# CBASS_CBASS_FW_45000000h register map
Vendor: Texas Instruments
Peripheral module from a debugger description file (folder AM275x).
Registers are 32-bit, read-write, reset 0x0 unless marked. A register's access mark holds for its fields unless they carry their own. Offsets are as the file gives them; lines under a group give offsets from that group; [hi:lo] are bit positions; {n}, {i} and the like mark numbered series; 'fields as' and 'values as' point back to an identical list; <NAME> marks a mode.

## cbass_fw
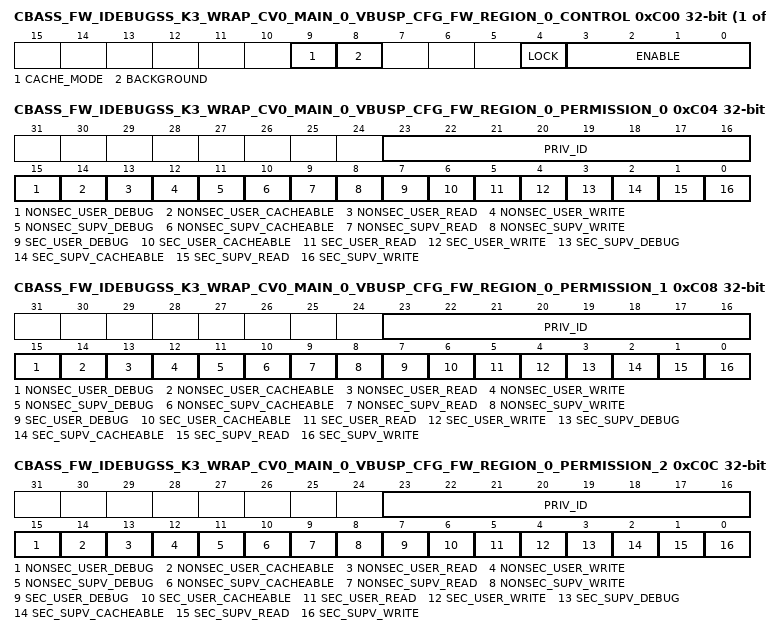
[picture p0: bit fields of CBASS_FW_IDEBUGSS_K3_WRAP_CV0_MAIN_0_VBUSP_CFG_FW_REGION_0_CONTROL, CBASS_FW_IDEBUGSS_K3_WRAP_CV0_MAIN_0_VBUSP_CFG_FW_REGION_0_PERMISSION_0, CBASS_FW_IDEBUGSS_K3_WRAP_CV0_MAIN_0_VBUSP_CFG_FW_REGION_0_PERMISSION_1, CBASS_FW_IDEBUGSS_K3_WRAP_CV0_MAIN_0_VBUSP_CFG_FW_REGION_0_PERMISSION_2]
{0xC00+0x20*i} CBASS_FW_IDEBUGSS_K3_WRAP_CV0_MAIN_0_VBUSP_CFG_FW_REGION_{i}_CONTROL access not given (i=0..3) — The FW Region {i} Control Register defines the control fields for the target Idebugss_k3_wrap_cv0_main_0.vbusp_cfg region {i} firewall.
  [9] CACHE_MODE rw — Cache mode for region. Set to 1 to check cache permissions. Set to 0 to ignore cache permissions. Reset Source: domain_default_rst_mod_g_rst_n
  [8] BACKGROUND rw — Background enable for region. There can be 1 backgroun region per FW and foreground regions can have overlapping addresses only with the background region. Reset Source: domain_default_rst_mod_g_rst_n
  [4] LOCK — Lock region. Once set region values cannot be modified. Reset Source: domain_default_rst_mod_g_rst_n (access R/W1TS)
  [3:0] ENABLE rw — Enable region. A value of 0xA enables, others disable. Reset Source: domain_default_rst_mod_g_rst_n
{0xC04+0x20*i} CBASS_FW_IDEBUGSS_K3_WRAP_CV0_MAIN_0_VBUSP_CFG_FW_REGION_{i}_PERMISSION_0 (i=0..3) — The FW Region {i} Permission 0 Register defines the permissions for the target Idebugss_k3_wrap_cv0_main_0.vbusp_cfg region {i} firewall.
  [23:16] PRIV_ID — Allowed privid. Reset Source: domain_default_rst_mod_g_rst_n
  [15] NONSEC_USER_DEBUG — Non-secure user debug allowed. Reset Source: domain_default_rst_mod_g_rst_n
  [14] NONSEC_USER_CACHEABLE — Non-secure user cacheable allowed. Reset Source: domain_default_rst_mod_g_rst_n
  [13] NONSEC_USER_READ — Non-secure user read allowed. Reset Source: domain_default_rst_mod_g_rst_n
  [12] NONSEC_USER_WRITE — Non-secure user write allowed. Reset Source: domain_default_rst_mod_g_rst_n
  [11] NONSEC_SUPV_DEBUG — Non-secure supervisor debug allowed. Reset Source: domain_default_rst_mod_g_rst_n
  [10] NONSEC_SUPV_CACHEABLE — Non-secure supervisor cacheable allowed. Reset Source: domain_default_rst_mod_g_rst_n
  [9] NONSEC_SUPV_READ — Non-secure supervisor read allowed. Reset Source: domain_default_rst_mod_g_rst_n
  [8] NONSEC_SUPV_WRITE — Non-secure supervisor write allowed. Reset Source: domain_default_rst_mod_g_rst_n
  [7] SEC_USER_DEBUG — Secure user debug allowed. Reset Source: domain_default_rst_mod_g_rst_n
  [6] SEC_USER_CACHEABLE — Secure user cacheable allowed. Reset Source: domain_default_rst_mod_g_rst_n
  [5] SEC_USER_READ — Secure user read allowed. Reset Source: domain_default_rst_mod_g_rst_n
  [4] SEC_USER_WRITE — Secure user write allowed. Reset Source: domain_default_rst_mod_g_rst_n
  [3] SEC_SUPV_DEBUG — Secure supervisor debug allowed. Reset Source: domain_default_rst_mod_g_rst_n
  [2] SEC_SUPV_CACHEABLE — Secure supervisor cacheable allowed. Reset Source: domain_default_rst_mod_g_rst_n
  [1] SEC_SUPV_READ — Secure supervisor read allowed. Reset Source: domain_default_rst_mod_g_rst_n
  [0] SEC_SUPV_WRITE — Secure supervisor write allowed. Reset Source: domain_default_rst_mod_g_rst_n
{0xC08+0x20*i} CBASS_FW_IDEBUGSS_K3_WRAP_CV0_MAIN_0_VBUSP_CFG_FW_REGION_{i}_PERMISSION_1 (i=0..3) — The FW Region {i} Permission 1 Register defines the permissions for the target Idebugss_k3_wrap_cv0_main_0.vbusp_cfg region {i} firewall.
  fields as CBASS_FW_IDEBUGSS_K3_WRAP_CV0_MAIN_0_VBUSP_CFG_FW_REGION_0_PERMISSION_0
{0xC0C+0x20*i} CBASS_FW_IDEBUGSS_K3_WRAP_CV0_MAIN_0_VBUSP_CFG_FW_REGION_{i}_PERMISSION_2 (i=0..3) — The FW Region {i} Permission 2 Register defines the permissions for the target Idebugss_k3_wrap_cv0_main_0.vbusp_cfg region {i} firewall.
  fields as CBASS_FW_IDEBUGSS_K3_WRAP_CV0_MAIN_0_VBUSP_CFG_FW_REGION_0_PERMISSION_0
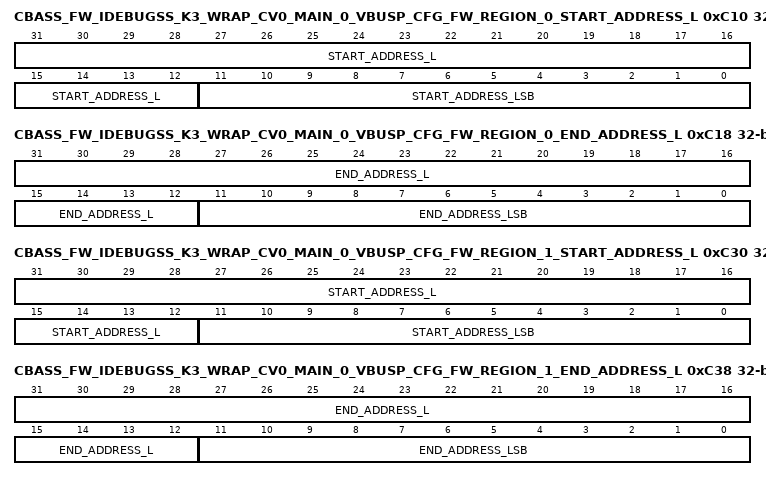
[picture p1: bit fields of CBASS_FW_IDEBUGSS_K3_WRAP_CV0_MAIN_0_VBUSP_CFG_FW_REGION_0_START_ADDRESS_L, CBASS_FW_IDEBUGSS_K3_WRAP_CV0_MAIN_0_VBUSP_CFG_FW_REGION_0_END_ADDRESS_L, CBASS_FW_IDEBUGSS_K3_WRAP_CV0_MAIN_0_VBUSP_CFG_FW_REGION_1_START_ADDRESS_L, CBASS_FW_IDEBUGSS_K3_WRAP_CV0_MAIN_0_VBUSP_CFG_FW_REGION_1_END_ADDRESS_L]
0xC10 CBASS_FW_IDEBUGSS_K3_WRAP_CV0_MAIN_0_VBUSP_CFG_FW_REGION_0_START_ADDRESS_L access per field — The FW Region 0 Start Address Low Register defines the start address bits 31 to 0 for the target Idebugss_k3_wrap_cv0_main_0.vbusp_cfg region 0 firewall.
  [31:12] START_ADDRESS_L rw — Start address bits 31 to 12. Lowest 12 bits are forced to 0 as address must be 4KB aligned. Reset Source: domain_default_rst_mod_g_rst_n
  [11:0] START_ADDRESS_LSB ro — Start address bits 11 to 0 are forced to 0 as address must be 4KB aligned. Reset Source: domain_default_rst_mod_g_rst_n
{0xC14+0x20*i} CBASS_FW_IDEBUGSS_K3_WRAP_CV0_MAIN_0_VBUSP_CFG_FW_REGION_{i}_START_ADDRESS_H reset 0x7 (i=0..3) — The FW Region {i} Start Address High Register defines the start address bits 47 to 32 for the target Idebugss_k3_wrap_cv0_main_0.vbusp_cfg region {i} firewall.
  [15:0] START_ADDRESS_H — Start address bits 47 to 32. Reset Source: domain_default_rst_mod_g_rst_n
0xC18 CBASS_FW_IDEBUGSS_K3_WRAP_CV0_MAIN_0_VBUSP_CFG_FW_REGION_0_END_ADDRESS_L access per field reset 0xFFF — The FW Region 0 End Address Low Register defines the end address bits 31 to 0 to include for the target Idebugss_k3_wrap_cv0_main_0.vbusp_cfg region 0 firewall.
  [31:12] END_ADDRESS_L rw — End address bits 31 to 12 to include in the match. Lowest 12 bits are forced to 1s as address must be 4KB aligned. Reset Source: domain_default_rst_mod_g_rst_n
  [11:0] END_ADDRESS_LSB ro — End address bits 11 to 0 are forced to 1s as address must be 4KB aligned minus 1. Reset Source: domain_default_rst_mod_g_rst_n
{0xC1C+0x20*i} CBASS_FW_IDEBUGSS_K3_WRAP_CV0_MAIN_0_VBUSP_CFG_FW_REGION_{i}_END_ADDRESS_H reset 0x7 (i=0..3) — The FW Region {i} End Address High Register defines the end address bits 47 to 32 to include for the target Idebugss_k3_wrap_cv0_main_0.vbusp_cfg region {i} firewall.
  [15:0] END_ADDRESS_H — End address bits 47 to 32 to include in the match. Reset Source: domain_default_rst_mod_g_rst_n
0xC30 CBASS_FW_IDEBUGSS_K3_WRAP_CV0_MAIN_0_VBUSP_CFG_FW_REGION_1_START_ADDRESS_L access per field reset 0x1000 — The FW Region 1 Start Address Low Register defines the start address bits 31 to 0 for the target Idebugss_k3_wrap_cv0_main_0.vbusp_cfg region 1 firewall.
  fields as CBASS_FW_IDEBUGSS_K3_WRAP_CV0_MAIN_0_VBUSP_CFG_FW_REGION_0_START_ADDRESS_L
0xC38 CBASS_FW_IDEBUGSS_K3_WRAP_CV0_MAIN_0_VBUSP_CFG_FW_REGION_1_END_ADDRESS_L access per field reset 0x1FFF — The FW Region 1 End Address Low Register defines the end address bits 31 to 0 to include for the target Idebugss_k3_wrap_cv0_main_0.vbusp_cfg region 1 firewall.
  fields as CBASS_FW_IDEBUGSS_K3_WRAP_CV0_MAIN_0_VBUSP_CFG_FW_REGION_0_END_ADDRESS_L
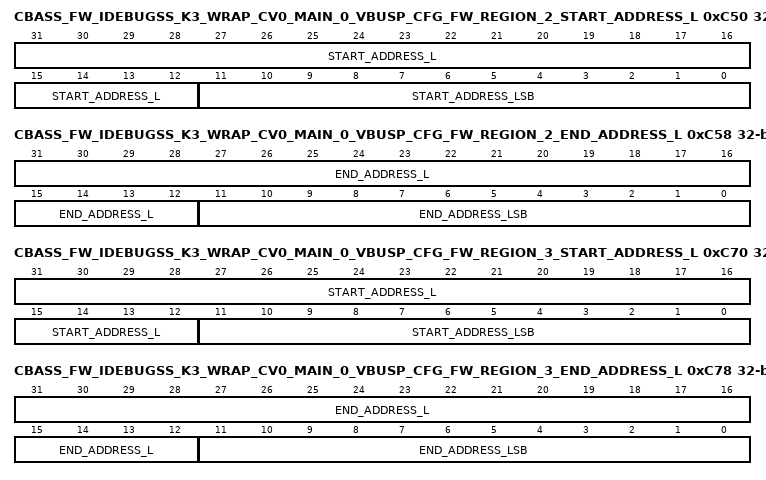
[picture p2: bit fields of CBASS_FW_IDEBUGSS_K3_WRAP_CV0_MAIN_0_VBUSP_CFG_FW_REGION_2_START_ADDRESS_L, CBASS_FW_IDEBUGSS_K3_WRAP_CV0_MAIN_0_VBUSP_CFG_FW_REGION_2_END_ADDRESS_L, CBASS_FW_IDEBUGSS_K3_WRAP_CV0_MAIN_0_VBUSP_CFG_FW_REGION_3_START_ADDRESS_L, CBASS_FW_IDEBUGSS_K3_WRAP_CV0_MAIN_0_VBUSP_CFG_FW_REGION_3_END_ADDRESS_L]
0xC50 CBASS_FW_IDEBUGSS_K3_WRAP_CV0_MAIN_0_VBUSP_CFG_FW_REGION_2_START_ADDRESS_L access per field reset 0x2000 — The FW Region 2 Start Address Low Register defines the start address bits 31 to 0 for the target Idebugss_k3_wrap_cv0_main_0.vbusp_cfg region 2 firewall.
  fields as CBASS_FW_IDEBUGSS_K3_WRAP_CV0_MAIN_0_VBUSP_CFG_FW_REGION_0_START_ADDRESS_L
0xC58 CBASS_FW_IDEBUGSS_K3_WRAP_CV0_MAIN_0_VBUSP_CFG_FW_REGION_2_END_ADDRESS_L access per field reset 0x2FFF — The FW Region 2 End Address Low Register defines the end address bits 31 to 0 to include for the target Idebugss_k3_wrap_cv0_main_0.vbusp_cfg region 2 firewall.
  fields as CBASS_FW_IDEBUGSS_K3_WRAP_CV0_MAIN_0_VBUSP_CFG_FW_REGION_0_END_ADDRESS_L
0xC70 CBASS_FW_IDEBUGSS_K3_WRAP_CV0_MAIN_0_VBUSP_CFG_FW_REGION_3_START_ADDRESS_L access per field reset 0x2000 — The FW Region 3 Start Address Low Register defines the start address bits 31 to 0 for the target Idebugss_k3_wrap_cv0_main_0.vbusp_cfg region 3 firewall.
  fields as CBASS_FW_IDEBUGSS_K3_WRAP_CV0_MAIN_0_VBUSP_CFG_FW_REGION_0_START_ADDRESS_L
0xC78 CBASS_FW_IDEBUGSS_K3_WRAP_CV0_MAIN_0_VBUSP_CFG_FW_REGION_3_END_ADDRESS_L access per field reset 0x2FFF — The FW Region 3 End Address Low Register defines the end address bits 31 to 0 to include for the target Idebugss_k3_wrap_cv0_main_0.vbusp_cfg region 3 firewall.
  fields as CBASS_FW_IDEBUGSS_K3_WRAP_CV0_MAIN_0_VBUSP_CFG_FW_REGION_0_END_ADDRESS_L
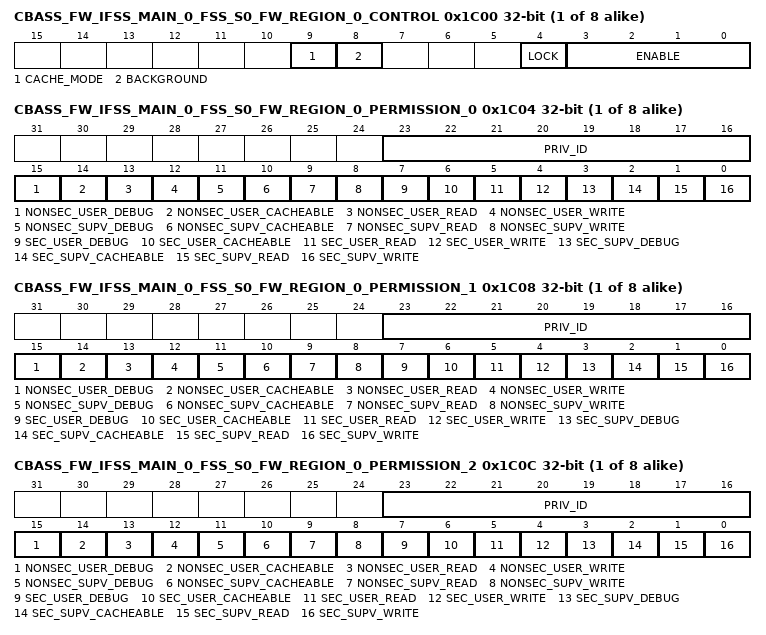
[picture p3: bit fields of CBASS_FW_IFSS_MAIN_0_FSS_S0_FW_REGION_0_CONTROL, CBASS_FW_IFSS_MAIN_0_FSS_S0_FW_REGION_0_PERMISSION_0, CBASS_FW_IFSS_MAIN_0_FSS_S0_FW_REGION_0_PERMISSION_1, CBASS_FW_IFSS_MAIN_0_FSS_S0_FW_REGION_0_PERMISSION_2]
{0x1C00+0x20*i} CBASS_FW_IFSS_MAIN_0_FSS_S0_FW_REGION_{i}_CONTROL access not given (i=0..7) — The FW Region {i} Control Register defines the control fields for the target Ifss_main_0.fss_s0 region {i} firewall.
  fields as CBASS_FW_IDEBUGSS_K3_WRAP_CV0_MAIN_0_VBUSP_CFG_FW_REGION_0_CONTROL
{0x1C04+0x20*i} CBASS_FW_IFSS_MAIN_0_FSS_S0_FW_REGION_{i}_PERMISSION_0 (i=0..7) — The FW Region {i} Permission 0 Register defines the permissions for the target Ifss_main_0.fss_s0 region {i} firewall.
  fields as CBASS_FW_IDEBUGSS_K3_WRAP_CV0_MAIN_0_VBUSP_CFG_FW_REGION_0_PERMISSION_0
{0x1C08+0x20*i} CBASS_FW_IFSS_MAIN_0_FSS_S0_FW_REGION_{i}_PERMISSION_1 (i=0..7) — The FW Region {i} Permission 1 Register defines the permissions for the target Ifss_main_0.fss_s0 region {i} firewall.
  fields as CBASS_FW_IDEBUGSS_K3_WRAP_CV0_MAIN_0_VBUSP_CFG_FW_REGION_0_PERMISSION_0
{0x1C0C+0x20*i} CBASS_FW_IFSS_MAIN_0_FSS_S0_FW_REGION_{i}_PERMISSION_2 (i=0..7) — The FW Region {i} Permission 2 Register defines the permissions for the target Ifss_main_0.fss_s0 region {i} firewall.
  fields as CBASS_FW_IDEBUGSS_K3_WRAP_CV0_MAIN_0_VBUSP_CFG_FW_REGION_0_PERMISSION_0
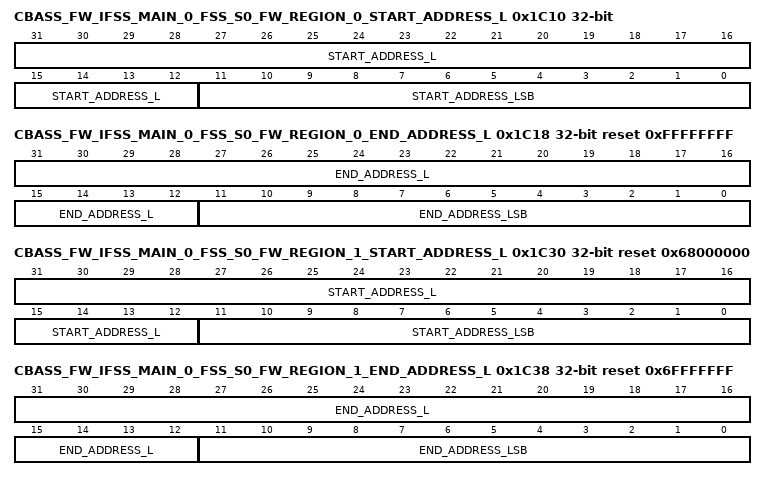
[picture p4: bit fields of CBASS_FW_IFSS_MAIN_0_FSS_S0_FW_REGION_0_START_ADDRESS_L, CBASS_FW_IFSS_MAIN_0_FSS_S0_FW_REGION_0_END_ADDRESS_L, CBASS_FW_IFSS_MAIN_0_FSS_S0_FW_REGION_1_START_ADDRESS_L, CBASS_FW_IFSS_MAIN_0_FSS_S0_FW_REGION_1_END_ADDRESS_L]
0x1C10 CBASS_FW_IFSS_MAIN_0_FSS_S0_FW_REGION_0_START_ADDRESS_L access per field — The FW Region 0 Start Address Low Register defines the start address bits 31 to 0 for the target Ifss_main_0.fss_s0 region 0 firewall.
  fields as CBASS_FW_IDEBUGSS_K3_WRAP_CV0_MAIN_0_VBUSP_CFG_FW_REGION_0_START_ADDRESS_L
0x1C14 CBASS_FW_IFSS_MAIN_0_FSS_S0_FW_REGION_0_START_ADDRESS_H reset 0x2 — The FW Region 0 Start Address High Register defines the start address bits 47 to 32 for the target Ifss_main_0.fss_s0 region 0 firewall.
  fields as CBASS_FW_IDEBUGSS_K3_WRAP_CV0_MAIN_0_VBUSP_CFG_FW_REGION_0_START_ADDRESS_H
0x1C18 CBASS_FW_IFSS_MAIN_0_FSS_S0_FW_REGION_0_END_ADDRESS_L access per field reset 0xFFFFFFFF — The FW Region 0 End Address Low Register defines the end address bits 31 to 0 to include for the target Ifss_main_0.fss_s0 region 0 firewall.
  fields as CBASS_FW_IDEBUGSS_K3_WRAP_CV0_MAIN_0_VBUSP_CFG_FW_REGION_0_END_ADDRESS_L
0x1C1C CBASS_FW_IFSS_MAIN_0_FSS_S0_FW_REGION_0_END_ADDRESS_H reset 0x2 — The FW Region 0 End Address High Register defines the end address bits 47 to 32 to include for the target Ifss_main_0.fss_s0 region 0 firewall.
  fields as CBASS_FW_IDEBUGSS_K3_WRAP_CV0_MAIN_0_VBUSP_CFG_FW_REGION_0_END_ADDRESS_H
0x1C30 CBASS_FW_IFSS_MAIN_0_FSS_S0_FW_REGION_1_START_ADDRESS_L access per field reset 0x68000000 — The FW Region 1 Start Address Low Register defines the start address bits 31 to 0 for the target Ifss_main_0.fss_s0 region 1 firewall.
  fields as CBASS_FW_IDEBUGSS_K3_WRAP_CV0_MAIN_0_VBUSP_CFG_FW_REGION_0_START_ADDRESS_L
0x1C34 CBASS_FW_IFSS_MAIN_0_FSS_S0_FW_REGION_1_START_ADDRESS_H — The FW Region 1 Start Address High Register defines the start address bits 47 to 32 for the target Ifss_main_0.fss_s0 region 1 firewall.
  fields as CBASS_FW_IDEBUGSS_K3_WRAP_CV0_MAIN_0_VBUSP_CFG_FW_REGION_0_START_ADDRESS_H
0x1C38 CBASS_FW_IFSS_MAIN_0_FSS_S0_FW_REGION_1_END_ADDRESS_L access per field reset 0x6FFFFFFF — The FW Region 1 End Address Low Register defines the end address bits 31 to 0 to include for the target Ifss_main_0.fss_s0 region 1 firewall.
  fields as CBASS_FW_IDEBUGSS_K3_WRAP_CV0_MAIN_0_VBUSP_CFG_FW_REGION_0_END_ADDRESS_L
0x1C3C CBASS_FW_IFSS_MAIN_0_FSS_S0_FW_REGION_1_END_ADDRESS_H — The FW Region 1 End Address High Register defines the end address bits 47 to 32 to include for the target Ifss_main_0.fss_s0 region 1 firewall.
  fields as CBASS_FW_IDEBUGSS_K3_WRAP_CV0_MAIN_0_VBUSP_CFG_FW_REGION_0_END_ADDRESS_H
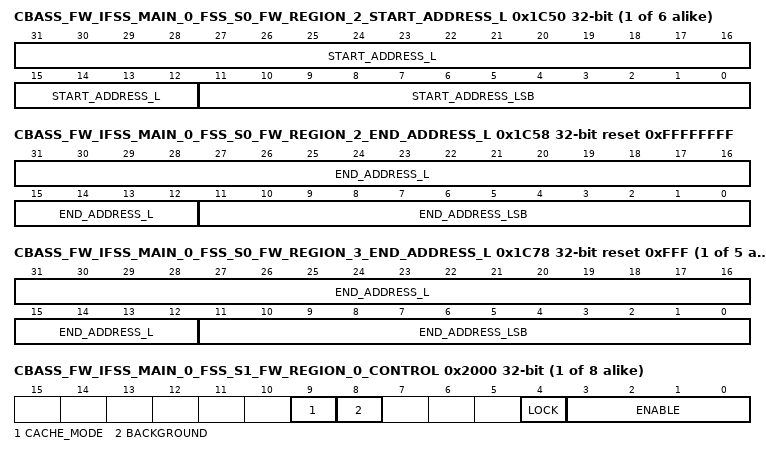
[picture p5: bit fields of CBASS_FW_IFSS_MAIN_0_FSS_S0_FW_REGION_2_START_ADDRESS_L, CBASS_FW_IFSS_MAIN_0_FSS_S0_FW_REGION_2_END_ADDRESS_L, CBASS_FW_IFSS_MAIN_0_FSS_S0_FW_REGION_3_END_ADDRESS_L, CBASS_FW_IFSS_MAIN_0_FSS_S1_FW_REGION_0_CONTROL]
{0x1C10+0x20*i} CBASS_FW_IFSS_MAIN_0_FSS_S0_FW_REGION_{i}_START_ADDRESS_L access per field (i=2..7) — The FW Region {i} Start Address Low Register defines the start address bits 31 to 0 for the target Ifss_main_0.fss_s0 region {i} firewall.
  fields as CBASS_FW_IDEBUGSS_K3_WRAP_CV0_MAIN_0_VBUSP_CFG_FW_REGION_0_START_ADDRESS_L
0x1C54 CBASS_FW_IFSS_MAIN_0_FSS_S0_FW_REGION_2_START_ADDRESS_H reset 0x3 — The FW Region 2 Start Address High Register defines the start address bits 47 to 32 for the target Ifss_main_0.fss_s0 region 2 firewall.
  fields as CBASS_FW_IDEBUGSS_K3_WRAP_CV0_MAIN_0_VBUSP_CFG_FW_REGION_0_START_ADDRESS_H
0x1C58 CBASS_FW_IFSS_MAIN_0_FSS_S0_FW_REGION_2_END_ADDRESS_L access per field reset 0xFFFFFFFF — The FW Region 2 End Address Low Register defines the end address bits 31 to 0 to include for the target Ifss_main_0.fss_s0 region 2 firewall.
  fields as CBASS_FW_IDEBUGSS_K3_WRAP_CV0_MAIN_0_VBUSP_CFG_FW_REGION_0_END_ADDRESS_L
0x1C5C CBASS_FW_IFSS_MAIN_0_FSS_S0_FW_REGION_2_END_ADDRESS_H reset 0x3 — The FW Region 2 End Address High Register defines the end address bits 47 to 32 to include for the target Ifss_main_0.fss_s0 region 2 firewall.
  fields as CBASS_FW_IDEBUGSS_K3_WRAP_CV0_MAIN_0_VBUSP_CFG_FW_REGION_0_END_ADDRESS_H
{0x1C14+0x20*i} CBASS_FW_IFSS_MAIN_0_FSS_S0_FW_REGION_{i}_START_ADDRESS_H (i=3..7) — The FW Region {i} Start Address High Register defines the start address bits 47 to 32 for the target Ifss_main_0.fss_s0 region {i} firewall.
  fields as CBASS_FW_IDEBUGSS_K3_WRAP_CV0_MAIN_0_VBUSP_CFG_FW_REGION_0_START_ADDRESS_H
{0x1C18+0x20*i} CBASS_FW_IFSS_MAIN_0_FSS_S0_FW_REGION_{i}_END_ADDRESS_L access per field reset 0xFFF (i=3..7) — The FW Region {i} End Address Low Register defines the end address bits 31 to 0 to include for the target Ifss_main_0.fss_s0 region {i} firewall.
  fields as CBASS_FW_IDEBUGSS_K3_WRAP_CV0_MAIN_0_VBUSP_CFG_FW_REGION_0_END_ADDRESS_L
{0x1C1C+0x20*i} CBASS_FW_IFSS_MAIN_0_FSS_S0_FW_REGION_{i}_END_ADDRESS_H (i=3..7) — The FW Region {i} End Address High Register defines the end address bits 47 to 32 to include for the target Ifss_main_0.fss_s0 region {i} firewall.
  fields as CBASS_FW_IDEBUGSS_K3_WRAP_CV0_MAIN_0_VBUSP_CFG_FW_REGION_0_END_ADDRESS_H
{0x2000+0x20*i} CBASS_FW_IFSS_MAIN_0_FSS_S1_FW_REGION_{i}_CONTROL access not given (i=0..7) — The FW Region {i} Control Register defines the control fields for the target Ifss_main_0.fss_s1 region {i} firewall.
  fields as CBASS_FW_IDEBUGSS_K3_WRAP_CV0_MAIN_0_VBUSP_CFG_FW_REGION_0_CONTROL
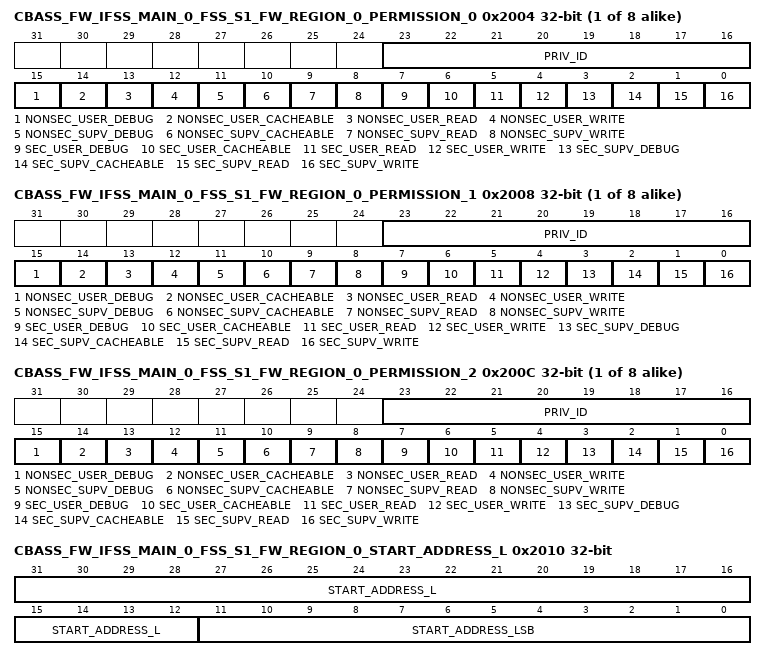
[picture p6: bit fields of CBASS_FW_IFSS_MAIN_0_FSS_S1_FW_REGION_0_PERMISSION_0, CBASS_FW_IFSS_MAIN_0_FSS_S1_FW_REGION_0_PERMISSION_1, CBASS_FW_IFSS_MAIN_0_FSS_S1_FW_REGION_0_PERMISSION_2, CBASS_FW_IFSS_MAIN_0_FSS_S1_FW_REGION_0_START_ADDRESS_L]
{0x2004+0x20*i} CBASS_FW_IFSS_MAIN_0_FSS_S1_FW_REGION_{i}_PERMISSION_0 (i=0..7) — The FW Region {i} Permission 0 Register defines the permissions for the target Ifss_main_0.fss_s1 region {i} firewall.
  fields as CBASS_FW_IDEBUGSS_K3_WRAP_CV0_MAIN_0_VBUSP_CFG_FW_REGION_0_PERMISSION_0
{0x2008+0x20*i} CBASS_FW_IFSS_MAIN_0_FSS_S1_FW_REGION_{i}_PERMISSION_1 (i=0..7) — The FW Region {i} Permission 1 Register defines the permissions for the target Ifss_main_0.fss_s1 region {i} firewall.
  fields as CBASS_FW_IDEBUGSS_K3_WRAP_CV0_MAIN_0_VBUSP_CFG_FW_REGION_0_PERMISSION_0
{0x200C+0x20*i} CBASS_FW_IFSS_MAIN_0_FSS_S1_FW_REGION_{i}_PERMISSION_2 (i=0..7) — The FW Region {i} Permission 2 Register defines the permissions for the target Ifss_main_0.fss_s1 region {i} firewall.
  fields as CBASS_FW_IDEBUGSS_K3_WRAP_CV0_MAIN_0_VBUSP_CFG_FW_REGION_0_PERMISSION_0
0x2010 CBASS_FW_IFSS_MAIN_0_FSS_S1_FW_REGION_0_START_ADDRESS_L access per field — The FW Region 0 Start Address Low Register defines the start address bits 31 to 0 for the target Ifss_main_0.fss_s1 region 0 firewall.
  fields as CBASS_FW_IDEBUGSS_K3_WRAP_CV0_MAIN_0_VBUSP_CFG_FW_REGION_0_START_ADDRESS_L
0x2014 CBASS_FW_IFSS_MAIN_0_FSS_S1_FW_REGION_0_START_ADDRESS_H reset 0x6 — The FW Region 0 Start Address High Register defines the start address bits 47 to 32 for the target Ifss_main_0.fss_s1 region 0 firewall.
  fields as CBASS_FW_IDEBUGSS_K3_WRAP_CV0_MAIN_0_VBUSP_CFG_FW_REGION_0_START_ADDRESS_H
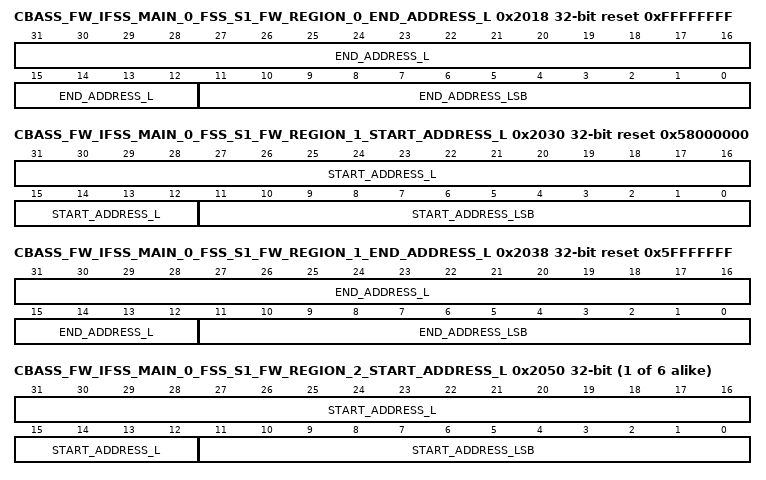
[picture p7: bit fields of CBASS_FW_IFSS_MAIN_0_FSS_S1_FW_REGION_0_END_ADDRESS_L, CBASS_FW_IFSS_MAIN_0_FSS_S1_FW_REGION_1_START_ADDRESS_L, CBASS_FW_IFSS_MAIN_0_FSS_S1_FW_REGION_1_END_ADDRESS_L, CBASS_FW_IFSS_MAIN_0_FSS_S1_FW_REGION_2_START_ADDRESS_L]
0x2018 CBASS_FW_IFSS_MAIN_0_FSS_S1_FW_REGION_0_END_ADDRESS_L access per field reset 0xFFFFFFFF — The FW Region 0 End Address Low Register defines the end address bits 31 to 0 to include for the target Ifss_main_0.fss_s1 region 0 firewall.
  fields as CBASS_FW_IDEBUGSS_K3_WRAP_CV0_MAIN_0_VBUSP_CFG_FW_REGION_0_END_ADDRESS_L
0x201C CBASS_FW_IFSS_MAIN_0_FSS_S1_FW_REGION_0_END_ADDRESS_H reset 0x6 — The FW Region 0 End Address High Register defines the end address bits 47 to 32 to include for the target Ifss_main_0.fss_s1 region 0 firewall.
  fields as CBASS_FW_IDEBUGSS_K3_WRAP_CV0_MAIN_0_VBUSP_CFG_FW_REGION_0_END_ADDRESS_H
0x2030 CBASS_FW_IFSS_MAIN_0_FSS_S1_FW_REGION_1_START_ADDRESS_L access per field reset 0x58000000 — The FW Region 1 Start Address Low Register defines the start address bits 31 to 0 for the target Ifss_main_0.fss_s1 region 1 firewall.
  fields as CBASS_FW_IDEBUGSS_K3_WRAP_CV0_MAIN_0_VBUSP_CFG_FW_REGION_0_START_ADDRESS_L
0x2034 CBASS_FW_IFSS_MAIN_0_FSS_S1_FW_REGION_1_START_ADDRESS_H — The FW Region 1 Start Address High Register defines the start address bits 47 to 32 for the target Ifss_main_0.fss_s1 region 1 firewall.
  fields as CBASS_FW_IDEBUGSS_K3_WRAP_CV0_MAIN_0_VBUSP_CFG_FW_REGION_0_START_ADDRESS_H
0x2038 CBASS_FW_IFSS_MAIN_0_FSS_S1_FW_REGION_1_END_ADDRESS_L access per field reset 0x5FFFFFFF — The FW Region 1 End Address Low Register defines the end address bits 31 to 0 to include for the target Ifss_main_0.fss_s1 region 1 firewall.
  fields as CBASS_FW_IDEBUGSS_K3_WRAP_CV0_MAIN_0_VBUSP_CFG_FW_REGION_0_END_ADDRESS_L
0x203C CBASS_FW_IFSS_MAIN_0_FSS_S1_FW_REGION_1_END_ADDRESS_H — The FW Region 1 End Address High Register defines the end address bits 47 to 32 to include for the target Ifss_main_0.fss_s1 region 1 firewall.
  fields as CBASS_FW_IDEBUGSS_K3_WRAP_CV0_MAIN_0_VBUSP_CFG_FW_REGION_0_END_ADDRESS_H
{0x2010+0x20*i} CBASS_FW_IFSS_MAIN_0_FSS_S1_FW_REGION_{i}_START_ADDRESS_L access per field (i=2..7) — The FW Region {i} Start Address Low Register defines the start address bits 31 to 0 for the target Ifss_main_0.fss_s1 region {i} firewall.
  fields as CBASS_FW_IDEBUGSS_K3_WRAP_CV0_MAIN_0_VBUSP_CFG_FW_REGION_0_START_ADDRESS_L
0x2054 CBASS_FW_IFSS_MAIN_0_FSS_S1_FW_REGION_2_START_ADDRESS_H reset 0xA — The FW Region 2 Start Address High Register defines the start address bits 47 to 32 for the target Ifss_main_0.fss_s1 region 2 firewall.
  fields as CBASS_FW_IDEBUGSS_K3_WRAP_CV0_MAIN_0_VBUSP_CFG_FW_REGION_0_START_ADDRESS_H
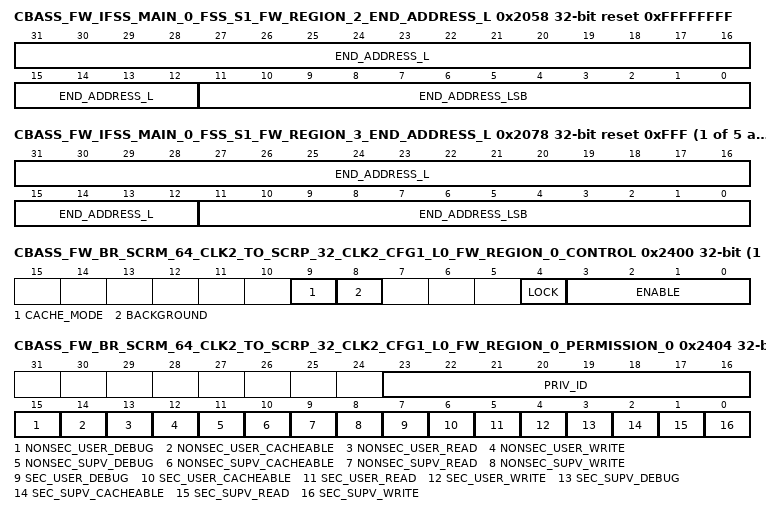
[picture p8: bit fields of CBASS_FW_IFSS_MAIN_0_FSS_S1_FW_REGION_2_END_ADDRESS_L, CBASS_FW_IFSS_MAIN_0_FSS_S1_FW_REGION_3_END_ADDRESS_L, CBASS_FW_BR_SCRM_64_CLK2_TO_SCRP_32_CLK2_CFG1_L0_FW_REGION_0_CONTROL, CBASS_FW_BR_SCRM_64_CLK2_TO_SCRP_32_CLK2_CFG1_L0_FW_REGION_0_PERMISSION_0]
0x2058 CBASS_FW_IFSS_MAIN_0_FSS_S1_FW_REGION_2_END_ADDRESS_L access per field reset 0xFFFFFFFF — The FW Region 2 End Address Low Register defines the end address bits 31 to 0 to include for the target Ifss_main_0.fss_s1 region 2 firewall.
  fields as CBASS_FW_IDEBUGSS_K3_WRAP_CV0_MAIN_0_VBUSP_CFG_FW_REGION_0_END_ADDRESS_L
0x205C CBASS_FW_IFSS_MAIN_0_FSS_S1_FW_REGION_2_END_ADDRESS_H reset 0xA — The FW Region 2 End Address High Register defines the end address bits 47 to 32 to include for the target Ifss_main_0.fss_s1 region 2 firewall.
  fields as CBASS_FW_IDEBUGSS_K3_WRAP_CV0_MAIN_0_VBUSP_CFG_FW_REGION_0_END_ADDRESS_H
{0x2014+0x20*i} CBASS_FW_IFSS_MAIN_0_FSS_S1_FW_REGION_{i}_START_ADDRESS_H (i=3..7) — The FW Region {i} Start Address High Register defines the start address bits 47 to 32 for the target Ifss_main_0.fss_s1 region {i} firewall.
  fields as CBASS_FW_IDEBUGSS_K3_WRAP_CV0_MAIN_0_VBUSP_CFG_FW_REGION_0_START_ADDRESS_H
{0x2018+0x20*i} CBASS_FW_IFSS_MAIN_0_FSS_S1_FW_REGION_{i}_END_ADDRESS_L access per field reset 0xFFF (i=3..7) — The FW Region {i} End Address Low Register defines the end address bits 31 to 0 to include for the target Ifss_main_0.fss_s1 region {i} firewall.
  fields as CBASS_FW_IDEBUGSS_K3_WRAP_CV0_MAIN_0_VBUSP_CFG_FW_REGION_0_END_ADDRESS_L
{0x201C+0x20*i} CBASS_FW_IFSS_MAIN_0_FSS_S1_FW_REGION_{i}_END_ADDRESS_H (i=3..7) — The FW Region {i} End Address High Register defines the end address bits 47 to 32 to include for the target Ifss_main_0.fss_s1 region {i} firewall.
  fields as CBASS_FW_IDEBUGSS_K3_WRAP_CV0_MAIN_0_VBUSP_CFG_FW_REGION_0_END_ADDRESS_H
{0x2400+0x20*i} CBASS_FW_BR_SCRM_64_CLK2_TO_SCRP_32_CLK2_CFG1_L0_FW_REGION_{i}_CONTROL access not given (i=0..31) — The FW Region {i} Control Register defines the control fields for the target br_SCRM_64_CLK2_to_SCRP_32_CLK2_CFG1_l0 region {i} firewall.
  fields as CBASS_FW_IDEBUGSS_K3_WRAP_CV0_MAIN_0_VBUSP_CFG_FW_REGION_0_CONTROL
{0x2404+0x20*i} CBASS_FW_BR_SCRM_64_CLK2_TO_SCRP_32_CLK2_CFG1_L0_FW_REGION_{i}_PERMISSION_0 (i=0..31) — The FW Region {i} Permission 0 Register defines the permissions for the target br_SCRM_64_CLK2_to_SCRP_32_CLK2_CFG1_l0 region {i} firewall.
  fields as CBASS_FW_IDEBUGSS_K3_WRAP_CV0_MAIN_0_VBUSP_CFG_FW_REGION_0_PERMISSION_0
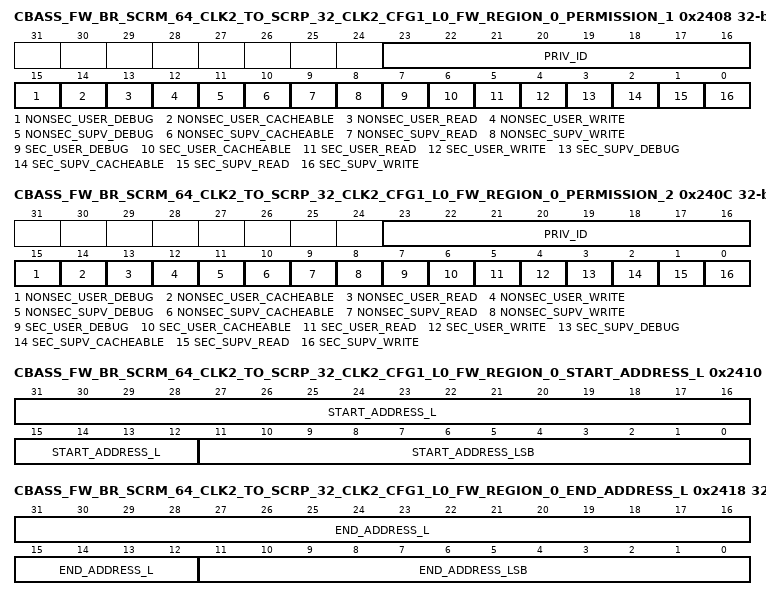
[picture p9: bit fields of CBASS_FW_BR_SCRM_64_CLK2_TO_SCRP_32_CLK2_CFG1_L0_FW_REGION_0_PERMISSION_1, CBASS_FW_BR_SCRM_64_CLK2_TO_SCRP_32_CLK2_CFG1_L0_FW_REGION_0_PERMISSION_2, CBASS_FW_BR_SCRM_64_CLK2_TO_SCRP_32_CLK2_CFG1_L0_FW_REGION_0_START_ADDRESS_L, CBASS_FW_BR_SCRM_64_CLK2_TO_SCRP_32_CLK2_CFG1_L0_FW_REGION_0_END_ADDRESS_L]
{0x2408+0x20*i} CBASS_FW_BR_SCRM_64_CLK2_TO_SCRP_32_CLK2_CFG1_L0_FW_REGION_{i}_PERMISSION_1 (i=0..31) — The FW Region {i} Permission 1 Register defines the permissions for the target br_SCRM_64_CLK2_to_SCRP_32_CLK2_CFG1_l0 region {i} firewall.
  fields as CBASS_FW_IDEBUGSS_K3_WRAP_CV0_MAIN_0_VBUSP_CFG_FW_REGION_0_PERMISSION_0
{0x240C+0x20*i} CBASS_FW_BR_SCRM_64_CLK2_TO_SCRP_32_CLK2_CFG1_L0_FW_REGION_{i}_PERMISSION_2 (i=0..31) — The FW Region {i} Permission 2 Register defines the permissions for the target br_SCRM_64_CLK2_to_SCRP_32_CLK2_CFG1_l0 region {i} firewall.
  fields as CBASS_FW_IDEBUGSS_K3_WRAP_CV0_MAIN_0_VBUSP_CFG_FW_REGION_0_PERMISSION_0
{0x2410+0x20*i} CBASS_FW_BR_SCRM_64_CLK2_TO_SCRP_32_CLK2_CFG1_L0_FW_REGION_{i}_START_ADDRESS_L access per field (i=0..31) — The FW Region {i} Start Address Low Register defines the start address bits 31 to 0 for the target br_SCRM_64_CLK2_to_SCRP_32_CLK2_CFG1_l0 region {i} firewall.
  fields as CBASS_FW_IDEBUGSS_K3_WRAP_CV0_MAIN_0_VBUSP_CFG_FW_REGION_0_START_ADDRESS_L
{0x2414+0x20*i} CBASS_FW_BR_SCRM_64_CLK2_TO_SCRP_32_CLK2_CFG1_L0_FW_REGION_{i}_START_ADDRESS_H (i=0..31) — The FW Region {i} Start Address High Register defines the start address bits 47 to 32 for the target br_SCRM_64_CLK2_to_SCRP_32_CLK2_CFG1_l0 region {i} firewall.
  fields as CBASS_FW_IDEBUGSS_K3_WRAP_CV0_MAIN_0_VBUSP_CFG_FW_REGION_0_START_ADDRESS_H
{0x2418+0x20*i} CBASS_FW_BR_SCRM_64_CLK2_TO_SCRP_32_CLK2_CFG1_L0_FW_REGION_{i}_END_ADDRESS_L access per field reset 0xFFF (i=0..31) — The FW Region {i} End Address Low Register defines the end address bits 31 to 0 to include for the target br_SCRM_64_CLK2_to_SCRP_32_CLK2_CFG1_l0 region {i} firewall.
  fields as CBASS_FW_IDEBUGSS_K3_WRAP_CV0_MAIN_0_VBUSP_CFG_FW_REGION_0_END_ADDRESS_L
{0x241C+0x20*i} CBASS_FW_BR_SCRM_64_CLK2_TO_SCRP_32_CLK2_CFG1_L0_FW_REGION_{i}_END_ADDRESS_H (i=0..31) — The FW Region {i} End Address High Register defines the end address bits 47 to 32 to include for the target br_SCRM_64_CLK2_to_SCRP_32_CLK2_CFG1_l0 region {i} firewall.
  fields as CBASS_FW_IDEBUGSS_K3_WRAP_CV0_MAIN_0_VBUSP_CFG_FW_REGION_0_END_ADDRESS_H
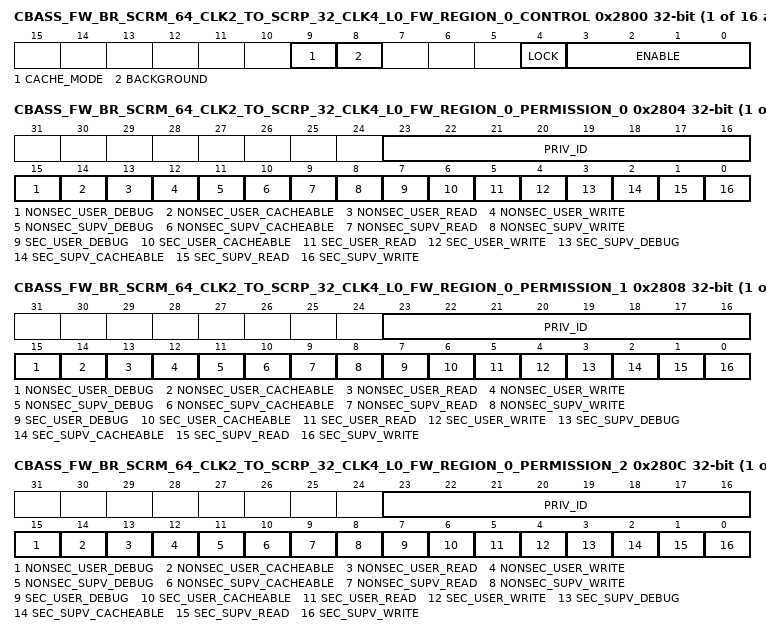
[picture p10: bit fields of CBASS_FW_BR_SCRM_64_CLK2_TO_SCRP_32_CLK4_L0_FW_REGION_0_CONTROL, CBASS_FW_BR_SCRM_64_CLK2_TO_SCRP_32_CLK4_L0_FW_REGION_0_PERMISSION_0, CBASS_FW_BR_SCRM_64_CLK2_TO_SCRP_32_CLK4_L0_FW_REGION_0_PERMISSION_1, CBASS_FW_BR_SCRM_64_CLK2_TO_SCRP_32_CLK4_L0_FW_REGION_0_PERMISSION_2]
{0x2800+0x20*i} CBASS_FW_BR_SCRM_64_CLK2_TO_SCRP_32_CLK4_L0_FW_REGION_{i}_CONTROL access not given (i=0..15) — The FW Region {i} Control Register defines the control fields for the target br_SCRM_64_CLK2_to_SCRP_32_CLK4_l0 region {i} firewall.
  fields as CBASS_FW_IDEBUGSS_K3_WRAP_CV0_MAIN_0_VBUSP_CFG_FW_REGION_0_CONTROL
{0x2804+0x20*i} CBASS_FW_BR_SCRM_64_CLK2_TO_SCRP_32_CLK4_L0_FW_REGION_{i}_PERMISSION_0 (i=0..15) — The FW Region {i} Permission 0 Register defines the permissions for the target br_SCRM_64_CLK2_to_SCRP_32_CLK4_l0 region {i} firewall.
  fields as CBASS_FW_IDEBUGSS_K3_WRAP_CV0_MAIN_0_VBUSP_CFG_FW_REGION_0_PERMISSION_0
{0x2808+0x20*i} CBASS_FW_BR_SCRM_64_CLK2_TO_SCRP_32_CLK4_L0_FW_REGION_{i}_PERMISSION_1 (i=0..15) — The FW Region {i} Permission 1 Register defines the permissions for the target br_SCRM_64_CLK2_to_SCRP_32_CLK4_l0 region {i} firewall.
  fields as CBASS_FW_IDEBUGSS_K3_WRAP_CV0_MAIN_0_VBUSP_CFG_FW_REGION_0_PERMISSION_0
{0x280C+0x20*i} CBASS_FW_BR_SCRM_64_CLK2_TO_SCRP_32_CLK4_L0_FW_REGION_{i}_PERMISSION_2 (i=0..15) — The FW Region {i} Permission 2 Register defines the permissions for the target br_SCRM_64_CLK2_to_SCRP_32_CLK4_l0 region {i} firewall.
  fields as CBASS_FW_IDEBUGSS_K3_WRAP_CV0_MAIN_0_VBUSP_CFG_FW_REGION_0_PERMISSION_0
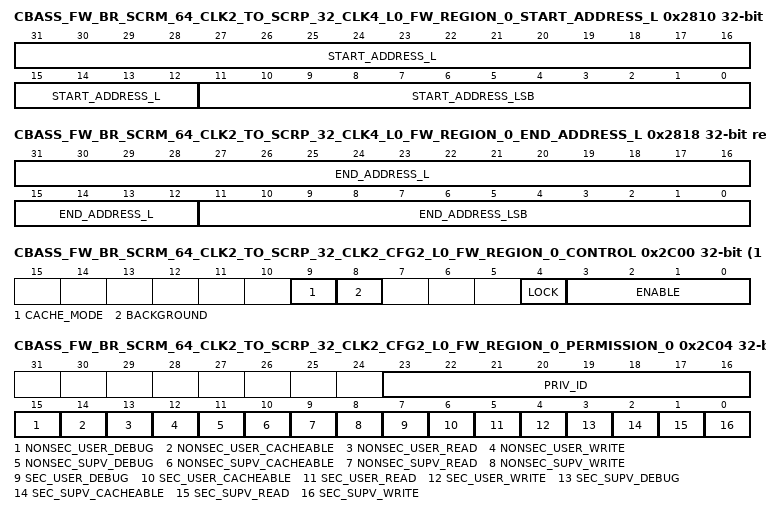
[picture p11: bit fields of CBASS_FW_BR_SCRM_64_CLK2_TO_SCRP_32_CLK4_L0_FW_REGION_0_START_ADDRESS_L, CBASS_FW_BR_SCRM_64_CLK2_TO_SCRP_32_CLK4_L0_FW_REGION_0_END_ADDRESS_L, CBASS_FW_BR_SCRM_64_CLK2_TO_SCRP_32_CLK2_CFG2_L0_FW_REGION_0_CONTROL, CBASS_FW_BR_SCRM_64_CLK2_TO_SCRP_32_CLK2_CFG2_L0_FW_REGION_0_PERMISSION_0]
{0x2810+0x20*i} CBASS_FW_BR_SCRM_64_CLK2_TO_SCRP_32_CLK4_L0_FW_REGION_{i}_START_ADDRESS_L access per field (i=0..15) — The FW Region {i} Start Address Low Register defines the start address bits 31 to 0 for the target br_SCRM_64_CLK2_to_SCRP_32_CLK4_l0 region {i} firewall.
  fields as CBASS_FW_IDEBUGSS_K3_WRAP_CV0_MAIN_0_VBUSP_CFG_FW_REGION_0_START_ADDRESS_L
{0x2814+0x20*i} CBASS_FW_BR_SCRM_64_CLK2_TO_SCRP_32_CLK4_L0_FW_REGION_{i}_START_ADDRESS_H (i=0..15) — The FW Region {i} Start Address High Register defines the start address bits 47 to 32 for the target br_SCRM_64_CLK2_to_SCRP_32_CLK4_l0 region {i} firewall.
  fields as CBASS_FW_IDEBUGSS_K3_WRAP_CV0_MAIN_0_VBUSP_CFG_FW_REGION_0_START_ADDRESS_H
{0x2818+0x20*i} CBASS_FW_BR_SCRM_64_CLK2_TO_SCRP_32_CLK4_L0_FW_REGION_{i}_END_ADDRESS_L access per field reset 0xFFF (i=0..15) — The FW Region {i} End Address Low Register defines the end address bits 31 to 0 to include for the target br_SCRM_64_CLK2_to_SCRP_32_CLK4_l0 region {i} firewall.
  fields as CBASS_FW_IDEBUGSS_K3_WRAP_CV0_MAIN_0_VBUSP_CFG_FW_REGION_0_END_ADDRESS_L
{0x281C+0x20*i} CBASS_FW_BR_SCRM_64_CLK2_TO_SCRP_32_CLK4_L0_FW_REGION_{i}_END_ADDRESS_H (i=0..15) — The FW Region {i} End Address High Register defines the end address bits 47 to 32 to include for the target br_SCRM_64_CLK2_to_SCRP_32_CLK4_l0 region {i} firewall.
  fields as CBASS_FW_IDEBUGSS_K3_WRAP_CV0_MAIN_0_VBUSP_CFG_FW_REGION_0_END_ADDRESS_H
{0x2C00+0x20*i} CBASS_FW_BR_SCRM_64_CLK2_TO_SCRP_32_CLK2_CFG2_L0_FW_REGION_{i}_CONTROL access not given (i=0..15) — The FW Region {i} Control Register defines the control fields for the target br_SCRM_64_CLK2_to_SCRP_32_CLK2_CFG2_l0 region {i} firewall.
  fields as CBASS_FW_IDEBUGSS_K3_WRAP_CV0_MAIN_0_VBUSP_CFG_FW_REGION_0_CONTROL
{0x2C04+0x20*i} CBASS_FW_BR_SCRM_64_CLK2_TO_SCRP_32_CLK2_CFG2_L0_FW_REGION_{i}_PERMISSION_0 (i=0..15) — The FW Region {i} Permission 0 Register defines the permissions for the target br_SCRM_64_CLK2_to_SCRP_32_CLK2_CFG2_l0 region {i} firewall.
  fields as CBASS_FW_IDEBUGSS_K3_WRAP_CV0_MAIN_0_VBUSP_CFG_FW_REGION_0_PERMISSION_0
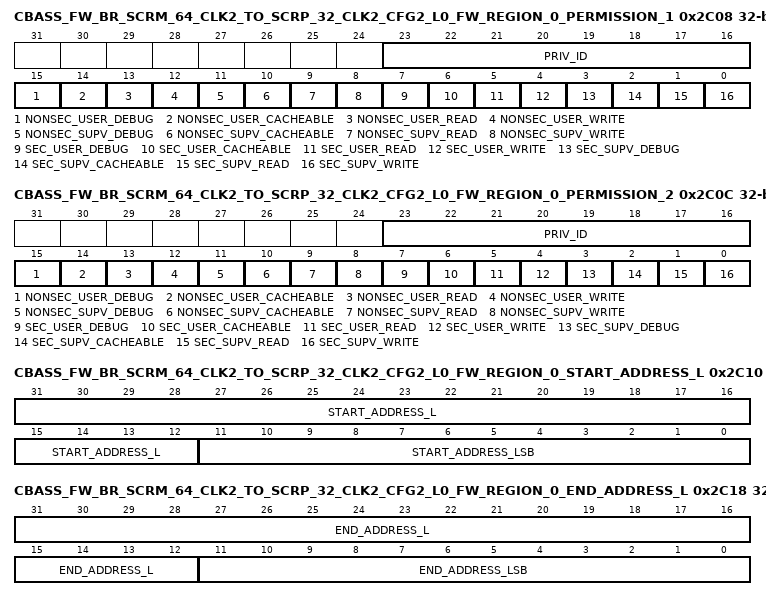
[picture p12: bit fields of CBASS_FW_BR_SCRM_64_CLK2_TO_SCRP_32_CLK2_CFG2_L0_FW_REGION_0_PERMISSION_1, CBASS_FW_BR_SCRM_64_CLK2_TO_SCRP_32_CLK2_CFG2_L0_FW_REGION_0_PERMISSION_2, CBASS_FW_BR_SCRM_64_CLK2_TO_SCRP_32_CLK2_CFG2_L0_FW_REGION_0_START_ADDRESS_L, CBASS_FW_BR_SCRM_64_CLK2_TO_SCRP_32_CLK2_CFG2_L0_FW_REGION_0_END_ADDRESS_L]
{0x2C08+0x20*i} CBASS_FW_BR_SCRM_64_CLK2_TO_SCRP_32_CLK2_CFG2_L0_FW_REGION_{i}_PERMISSION_1 (i=0..15) — The FW Region {i} Permission 1 Register defines the permissions for the target br_SCRM_64_CLK2_to_SCRP_32_CLK2_CFG2_l0 region {i} firewall.
  fields as CBASS_FW_IDEBUGSS_K3_WRAP_CV0_MAIN_0_VBUSP_CFG_FW_REGION_0_PERMISSION_0
{0x2C0C+0x20*i} CBASS_FW_BR_SCRM_64_CLK2_TO_SCRP_32_CLK2_CFG2_L0_FW_REGION_{i}_PERMISSION_2 (i=0..15) — The FW Region {i} Permission 2 Register defines the permissions for the target br_SCRM_64_CLK2_to_SCRP_32_CLK2_CFG2_l0 region {i} firewall.
  fields as CBASS_FW_IDEBUGSS_K3_WRAP_CV0_MAIN_0_VBUSP_CFG_FW_REGION_0_PERMISSION_0
{0x2C10+0x20*i} CBASS_FW_BR_SCRM_64_CLK2_TO_SCRP_32_CLK2_CFG2_L0_FW_REGION_{i}_START_ADDRESS_L access per field (i=0..15) — The FW Region {i} Start Address Low Register defines the start address bits 31 to 0 for the target br_SCRM_64_CLK2_to_SCRP_32_CLK2_CFG2_l0 region {i} firewall.
  fields as CBASS_FW_IDEBUGSS_K3_WRAP_CV0_MAIN_0_VBUSP_CFG_FW_REGION_0_START_ADDRESS_L
{0x2C14+0x20*i} CBASS_FW_BR_SCRM_64_CLK2_TO_SCRP_32_CLK2_CFG2_L0_FW_REGION_{i}_START_ADDRESS_H (i=0..15) — The FW Region {i} Start Address High Register defines the start address bits 47 to 32 for the target br_SCRM_64_CLK2_to_SCRP_32_CLK2_CFG2_l0 region {i} firewall.
  fields as CBASS_FW_IDEBUGSS_K3_WRAP_CV0_MAIN_0_VBUSP_CFG_FW_REGION_0_START_ADDRESS_H
{0x2C18+0x20*i} CBASS_FW_BR_SCRM_64_CLK2_TO_SCRP_32_CLK2_CFG2_L0_FW_REGION_{i}_END_ADDRESS_L access per field reset 0xFFF (i=0..15) — The FW Region {i} End Address Low Register defines the end address bits 31 to 0 to include for the target br_SCRM_64_CLK2_to_SCRP_32_CLK2_CFG2_l0 region {i} firewall.
  fields as CBASS_FW_IDEBUGSS_K3_WRAP_CV0_MAIN_0_VBUSP_CFG_FW_REGION_0_END_ADDRESS_L
{0x2C1C+0x20*i} CBASS_FW_BR_SCRM_64_CLK2_TO_SCRP_32_CLK2_CFG2_L0_FW_REGION_{i}_END_ADDRESS_H (i=0..15) — The FW Region {i} End Address High Register defines the end address bits 47 to 32 to include for the target br_SCRM_64_CLK2_to_SCRP_32_CLK2_CFG2_l0 region {i} firewall.
  fields as CBASS_FW_IDEBUGSS_K3_WRAP_CV0_MAIN_0_VBUSP_CFG_FW_REGION_0_END_ADDRESS_H
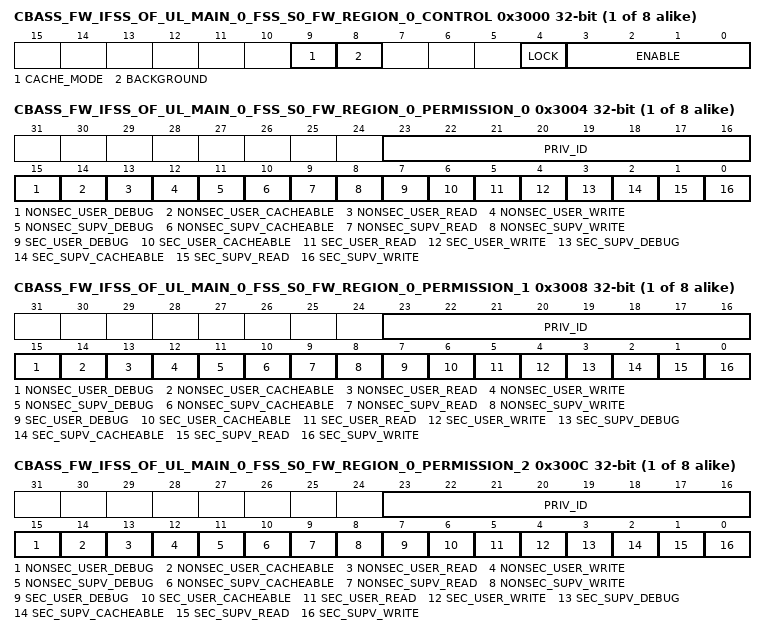
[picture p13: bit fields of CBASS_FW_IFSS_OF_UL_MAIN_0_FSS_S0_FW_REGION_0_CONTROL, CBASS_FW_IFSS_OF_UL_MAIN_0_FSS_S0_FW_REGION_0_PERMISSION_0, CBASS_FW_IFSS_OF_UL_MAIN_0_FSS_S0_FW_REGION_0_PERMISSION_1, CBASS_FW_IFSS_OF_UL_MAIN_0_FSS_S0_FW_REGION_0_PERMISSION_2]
{0x3000+0x20*i} CBASS_FW_IFSS_OF_UL_MAIN_0_FSS_S0_FW_REGION_{i}_CONTROL access not given (i=0..7) — The FW Region {i} Control Register defines the control fields for the target Ifss_of_ul_main_0.fss_s0 region {i} firewall.
  fields as CBASS_FW_IDEBUGSS_K3_WRAP_CV0_MAIN_0_VBUSP_CFG_FW_REGION_0_CONTROL
{0x3004+0x20*i} CBASS_FW_IFSS_OF_UL_MAIN_0_FSS_S0_FW_REGION_{i}_PERMISSION_0 (i=0..7) — The FW Region {i} Permission 0 Register defines the permissions for the target Ifss_of_ul_main_0.fss_s0 region {i} firewall.
  fields as CBASS_FW_IDEBUGSS_K3_WRAP_CV0_MAIN_0_VBUSP_CFG_FW_REGION_0_PERMISSION_0
{0x3008+0x20*i} CBASS_FW_IFSS_OF_UL_MAIN_0_FSS_S0_FW_REGION_{i}_PERMISSION_1 (i=0..7) — The FW Region {i} Permission 1 Register defines the permissions for the target Ifss_of_ul_main_0.fss_s0 region {i} firewall.
  fields as CBASS_FW_IDEBUGSS_K3_WRAP_CV0_MAIN_0_VBUSP_CFG_FW_REGION_0_PERMISSION_0
{0x300C+0x20*i} CBASS_FW_IFSS_OF_UL_MAIN_0_FSS_S0_FW_REGION_{i}_PERMISSION_2 (i=0..7) — The FW Region {i} Permission 2 Register defines the permissions for the target Ifss_of_ul_main_0.fss_s0 region {i} firewall.
  fields as CBASS_FW_IDEBUGSS_K3_WRAP_CV0_MAIN_0_VBUSP_CFG_FW_REGION_0_PERMISSION_0
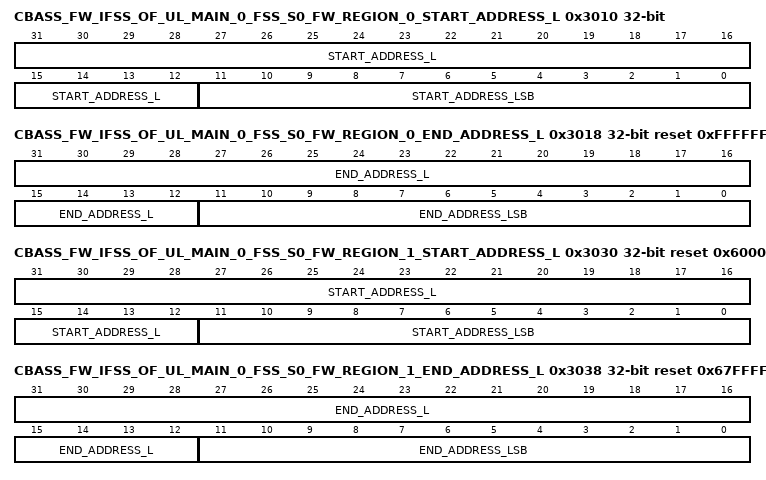
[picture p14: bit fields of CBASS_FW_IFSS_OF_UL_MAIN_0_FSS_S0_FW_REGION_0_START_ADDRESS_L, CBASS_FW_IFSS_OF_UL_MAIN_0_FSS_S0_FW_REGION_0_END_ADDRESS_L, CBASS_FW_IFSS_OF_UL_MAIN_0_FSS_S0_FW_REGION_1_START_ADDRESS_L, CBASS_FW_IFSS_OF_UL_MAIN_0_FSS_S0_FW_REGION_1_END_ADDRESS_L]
0x3010 CBASS_FW_IFSS_OF_UL_MAIN_0_FSS_S0_FW_REGION_0_START_ADDRESS_L access per field — The FW Region 0 Start Address Low Register defines the start address bits 31 to 0 for the target Ifss_of_ul_main_0.fss_s0 region 0 firewall.
  fields as CBASS_FW_IDEBUGSS_K3_WRAP_CV0_MAIN_0_VBUSP_CFG_FW_REGION_0_START_ADDRESS_L
0x3014 CBASS_FW_IFSS_OF_UL_MAIN_0_FSS_S0_FW_REGION_0_START_ADDRESS_H reset 0x4 — The FW Region 0 Start Address High Register defines the start address bits 47 to 32 for the target Ifss_of_ul_main_0.fss_s0 region 0 firewall.
  fields as CBASS_FW_IDEBUGSS_K3_WRAP_CV0_MAIN_0_VBUSP_CFG_FW_REGION_0_START_ADDRESS_H
0x3018 CBASS_FW_IFSS_OF_UL_MAIN_0_FSS_S0_FW_REGION_0_END_ADDRESS_L access per field reset 0xFFFFFFFF — The FW Region 0 End Address Low Register defines the end address bits 31 to 0 to include for the target Ifss_of_ul_main_0.fss_s0 region 0 firewall.
  fields as CBASS_FW_IDEBUGSS_K3_WRAP_CV0_MAIN_0_VBUSP_CFG_FW_REGION_0_END_ADDRESS_L
0x301C CBASS_FW_IFSS_OF_UL_MAIN_0_FSS_S0_FW_REGION_0_END_ADDRESS_H reset 0x4 — The FW Region 0 End Address High Register defines the end address bits 47 to 32 to include for the target Ifss_of_ul_main_0.fss_s0 region 0 firewall.
  fields as CBASS_FW_IDEBUGSS_K3_WRAP_CV0_MAIN_0_VBUSP_CFG_FW_REGION_0_END_ADDRESS_H
0x3030 CBASS_FW_IFSS_OF_UL_MAIN_0_FSS_S0_FW_REGION_1_START_ADDRESS_L access per field reset 0x60000000 — The FW Region 1 Start Address Low Register defines the start address bits 31 to 0 for the target Ifss_of_ul_main_0.fss_s0 region 1 firewall.
  fields as CBASS_FW_IDEBUGSS_K3_WRAP_CV0_MAIN_0_VBUSP_CFG_FW_REGION_0_START_ADDRESS_L
0x3034 CBASS_FW_IFSS_OF_UL_MAIN_0_FSS_S0_FW_REGION_1_START_ADDRESS_H — The FW Region 1 Start Address High Register defines the start address bits 47 to 32 for the target Ifss_of_ul_main_0.fss_s0 region 1 firewall.
  fields as CBASS_FW_IDEBUGSS_K3_WRAP_CV0_MAIN_0_VBUSP_CFG_FW_REGION_0_START_ADDRESS_H
0x3038 CBASS_FW_IFSS_OF_UL_MAIN_0_FSS_S0_FW_REGION_1_END_ADDRESS_L access per field reset 0x67FFFFFF — The FW Region 1 End Address Low Register defines the end address bits 31 to 0 to include for the target Ifss_of_ul_main_0.fss_s0 region 1 firewall.
  fields as CBASS_FW_IDEBUGSS_K3_WRAP_CV0_MAIN_0_VBUSP_CFG_FW_REGION_0_END_ADDRESS_L
0x303C CBASS_FW_IFSS_OF_UL_MAIN_0_FSS_S0_FW_REGION_1_END_ADDRESS_H — The FW Region 1 End Address High Register defines the end address bits 47 to 32 to include for the target Ifss_of_ul_main_0.fss_s0 region 1 firewall.
  fields as CBASS_FW_IDEBUGSS_K3_WRAP_CV0_MAIN_0_VBUSP_CFG_FW_REGION_0_END_ADDRESS_H
{0x3010+0x20*i} CBASS_FW_IFSS_OF_UL_MAIN_0_FSS_S0_FW_REGION_{i}_START_ADDRESS_L access per field (i=2..7) — The FW Region {i} Start Address Low Register defines the start address bits 31 to 0 for the target Ifss_of_ul_main_0.fss_s0 region {i} firewall.
  fields as CBASS_FW_IDEBUGSS_K3_WRAP_CV0_MAIN_0_VBUSP_CFG_FW_REGION_0_START_ADDRESS_L
0x3054 CBASS_FW_IFSS_OF_UL_MAIN_0_FSS_S0_FW_REGION_2_START_ADDRESS_H reset 0x5 — The FW Region 2 Start Address High Register defines the start address bits 47 to 32 for the target Ifss_of_ul_main_0.fss_s0 region 2 firewall.
  fields as CBASS_FW_IDEBUGSS_K3_WRAP_CV0_MAIN_0_VBUSP_CFG_FW_REGION_0_START_ADDRESS_H
0x3058 CBASS_FW_IFSS_OF_UL_MAIN_0_FSS_S0_FW_REGION_2_END_ADDRESS_L access per field reset 0xFFFFFFFF — The FW Region 2 End Address Low Register defines the end address bits 31 to 0 to include for the target Ifss_of_ul_main_0.fss_s0 region 2 firewall.
  fields as CBASS_FW_IDEBUGSS_K3_WRAP_CV0_MAIN_0_VBUSP_CFG_FW_REGION_0_END_ADDRESS_L
0x305C CBASS_FW_IFSS_OF_UL_MAIN_0_FSS_S0_FW_REGION_2_END_ADDRESS_H reset 0x5 — The FW Region 2 End Address High Register defines the end address bits 47 to 32 to include for the target Ifss_of_ul_main_0.fss_s0 region 2 firewall.
  fields as CBASS_FW_IDEBUGSS_K3_WRAP_CV0_MAIN_0_VBUSP_CFG_FW_REGION_0_END_ADDRESS_H
{0x3014+0x20*i} CBASS_FW_IFSS_OF_UL_MAIN_0_FSS_S0_FW_REGION_{i}_START_ADDRESS_H (i=3..7) — The FW Region {i} Start Address High Register defines the start address bits 47 to 32 for the target Ifss_of_ul_main_0.fss_s0 region {i} firewall.
  fields as CBASS_FW_IDEBUGSS_K3_WRAP_CV0_MAIN_0_VBUSP_CFG_FW_REGION_0_START_ADDRESS_H
{0x3018+0x20*i} CBASS_FW_IFSS_OF_UL_MAIN_0_FSS_S0_FW_REGION_{i}_END_ADDRESS_L access per field reset 0xFFF (i=3..7) — The FW Region {i} End Address Low Register defines the end address bits 31 to 0 to include for the target Ifss_of_ul_main_0.fss_s0 region {i} firewall.
  fields as CBASS_FW_IDEBUGSS_K3_WRAP_CV0_MAIN_0_VBUSP_CFG_FW_REGION_0_END_ADDRESS_L
{0x301C+0x20*i} CBASS_FW_IFSS_OF_UL_MAIN_0_FSS_S0_FW_REGION_{i}_END_ADDRESS_H (i=3..7) — The FW Region {i} End Address High Register defines the end address bits 47 to 32 to include for the target Ifss_of_ul_main_0.fss_s0 region {i} firewall.
  fields as CBASS_FW_IDEBUGSS_K3_WRAP_CV0_MAIN_0_VBUSP_CFG_FW_REGION_0_END_ADDRESS_H
0x3400 CBASS_FW_IMCRC64_MAIN_0_S_CFG_FW_REGION_0_CONTROL access not given — The FW Region 0 Control Register defines the control fields for the target Imcrc64_main_0.s_cfg region 0 firewall.
  fields as CBASS_FW_IDEBUGSS_K3_WRAP_CV0_MAIN_0_VBUSP_CFG_FW_REGION_0_CONTROL
{0x3404+4i} CBASS_FW_IMCRC64_MAIN_0_S_CFG_FW_REGION_0_PERMISSION_{i} (i=0..2) — The FW Region 0 Permission {i} Register defines the permissions for the target Imcrc64_main_0.s_cfg region 0 firewall.
  fields as CBASS_FW_IDEBUGSS_K3_WRAP_CV0_MAIN_0_VBUSP_CFG_FW_REGION_0_PERMISSION_0
0x3410 CBASS_FW_IMCRC64_MAIN_0_S_CFG_FW_REGION_0_START_ADDRESS_L access per field reset 0x30300000 — The FW Region 0 Start Address Low Register defines the start address bits 31 to 0 for the target Imcrc64_main_0.s_cfg region 0 firewall.
  fields as CBASS_FW_IDEBUGSS_K3_WRAP_CV0_MAIN_0_VBUSP_CFG_FW_REGION_0_START_ADDRESS_L
0x3414 CBASS_FW_IMCRC64_MAIN_0_S_CFG_FW_REGION_0_START_ADDRESS_H — The FW Region 0 Start Address High Register defines the start address bits 47 to 32 for the target Imcrc64_main_0.s_cfg region 0 firewall.
  fields as CBASS_FW_IDEBUGSS_K3_WRAP_CV0_MAIN_0_VBUSP_CFG_FW_REGION_0_START_ADDRESS_H
0x3418 CBASS_FW_IMCRC64_MAIN_0_S_CFG_FW_REGION_0_END_ADDRESS_L access per field reset 0x30300FFF — The FW Region 0 End Address Low Register defines the end address bits 31 to 0 to include for the target Imcrc64_main_0.s_cfg region 0 firewall.
  fields as CBASS_FW_IDEBUGSS_K3_WRAP_CV0_MAIN_0_VBUSP_CFG_FW_REGION_0_END_ADDRESS_L
0x341C CBASS_FW_IMCRC64_MAIN_0_S_CFG_FW_REGION_0_END_ADDRESS_H — The FW Region 0 End Address High Register defines the end address bits 47 to 32 to include for the target Imcrc64_main_0.s_cfg region 0 firewall.
  fields as CBASS_FW_IDEBUGSS_K3_WRAP_CV0_MAIN_0_VBUSP_CFG_FW_REGION_0_END_ADDRESS_H
{0x5400+0x20*i} CBASS_FW_EXPORT_AM275_MAIN_DATA_CBASS_TO_AM275_MAIN_AUDIO_CBASS_DATA_L0_FW_REGION_{i}_CONTROL access not given (i=0..7) — The FW Region {i} Control Register defines the control fields for the target export_am275_main_data_cbass_to_am275_main_audio_cbass_data_l0.slv region {i} firewall.
  fields as CBASS_FW_IDEBUGSS_K3_WRAP_CV0_MAIN_0_VBUSP_CFG_FW_REGION_0_CONTROL
{0x5404+0x20*i} CBASS_FW_EXPORT_AM275_MAIN_DATA_CBASS_TO_AM275_MAIN_AUDIO_CBASS_DATA_L0_FW_REGION_{i}_PERMISSION_0 (i=0..7) — The FW Region {i} Permission 0 Register defines the permissions for the target export_am275_main_data_cbass_to_am275_main_audio_cbass_data_l0.slv region {i} firewall.
  fields as CBASS_FW_IDEBUGSS_K3_WRAP_CV0_MAIN_0_VBUSP_CFG_FW_REGION_0_PERMISSION_0
{0x5408+0x20*i} CBASS_FW_EXPORT_AM275_MAIN_DATA_CBASS_TO_AM275_MAIN_AUDIO_CBASS_DATA_L0_FW_REGION_{i}_PERMISSION_1 (i=0..7) — The FW Region {i} Permission 1 Register defines the permissions for the target export_am275_main_data_cbass_to_am275_main_audio_cbass_data_l0.slv region {i} firewall.
  fields as CBASS_FW_IDEBUGSS_K3_WRAP_CV0_MAIN_0_VBUSP_CFG_FW_REGION_0_PERMISSION_0
{0x540C+0x20*i} CBASS_FW_EXPORT_AM275_MAIN_DATA_CBASS_TO_AM275_MAIN_AUDIO_CBASS_DATA_L0_FW_REGION_{i}_PERMISSION_2 (i=0..7) — The FW Region {i} Permission 2 Register defines the permissions for the target export_am275_main_data_cbass_to_am275_main_audio_cbass_data_l0.slv region {i} firewall.
  fields as CBASS_FW_IDEBUGSS_K3_WRAP_CV0_MAIN_0_VBUSP_CFG_FW_REGION_0_PERMISSION_0
{0x5410+0x20*i} CBASS_FW_EXPORT_AM275_MAIN_DATA_CBASS_TO_AM275_MAIN_AUDIO_CBASS_DATA_L0_FW_REGION_{i}_START_ADDRESS_L access per field (i=0..7) — The FW Region {i} Start Address Low Register defines the start address bits 31 to 0 for the target export_am275_main_data_cbass_to_am275_main_audio_cbass_data_l0.slv region {i} firewall.
  fields as CBASS_FW_IDEBUGSS_K3_WRAP_CV0_MAIN_0_VBUSP_CFG_FW_REGION_0_START_ADDRESS_L
{0x5414+0x20*i} CBASS_FW_EXPORT_AM275_MAIN_DATA_CBASS_TO_AM275_MAIN_AUDIO_CBASS_DATA_L0_FW_REGION_{i}_START_ADDRESS_H (i=0..7) — The FW Region {i} Start Address High Register defines the start address bits 47 to 32 for the target export_am275_main_data_cbass_to_am275_main_audio_cbass_data_l0.slv region {i} firewall.
  fields as CBASS_FW_IDEBUGSS_K3_WRAP_CV0_MAIN_0_VBUSP_CFG_FW_REGION_0_START_ADDRESS_H
{0x5418+0x20*i} CBASS_FW_EXPORT_AM275_MAIN_DATA_CBASS_TO_AM275_MAIN_AUDIO_CBASS_DATA_L0_FW_REGION_{i}_END_ADDRESS_L access per field reset 0xFFF (i=0..7) — The FW Region {i} End Address Low Register defines the end address bits 31 to 0 to include for the target export_am275_main_data_cbass_to_am275_main_audio_cbass_data_l0.slv region {i} firewall.
  fields as CBASS_FW_IDEBUGSS_K3_WRAP_CV0_MAIN_0_VBUSP_CFG_FW_REGION_0_END_ADDRESS_L
{0x541C+0x20*i} CBASS_FW_EXPORT_AM275_MAIN_DATA_CBASS_TO_AM275_MAIN_AUDIO_CBASS_DATA_L0_FW_REGION_{i}_END_ADDRESS_H (i=0..7) — The FW Region {i} End Address High Register defines the end address bits 47 to 32 to include for the target export_am275_main_data_cbass_to_am275_main_audio_cbass_data_l0.slv region {i} firewall.
  fields as CBASS_FW_IDEBUGSS_K3_WRAP_CV0_MAIN_0_VBUSP_CFG_FW_REGION_0_END_ADDRESS_H
0x5800 CBASS_FW_IPULSAR_SL_MAIN_0_CPU0_SLV_FW_REGION_0_CONTROL access not given — The FW Region 0 Control Register defines the control fields for the target Ipulsar_sl_main_0.cpu0_slv region 0 firewall.
  fields as CBASS_FW_IDEBUGSS_K3_WRAP_CV0_MAIN_0_VBUSP_CFG_FW_REGION_0_CONTROL
{0x5804+4i} CBASS_FW_IPULSAR_SL_MAIN_0_CPU0_SLV_FW_REGION_0_PERMISSION_{i} (i=0..2) — The FW Region 0 Permission {i} Register defines the permissions for the target Ipulsar_sl_main_0.cpu0_slv region 0 firewall.
  fields as CBASS_FW_IDEBUGSS_K3_WRAP_CV0_MAIN_0_VBUSP_CFG_FW_REGION_0_PERMISSION_0
0x5810 CBASS_FW_IPULSAR_SL_MAIN_0_CPU0_SLV_FW_REGION_0_START_ADDRESS_L access per field reset 0x5C00000 — The FW Region 0 Start Address Low Register defines the start address bits 31 to 0 for the target Ipulsar_sl_main_0.cpu0_slv region 0 firewall.
  fields as CBASS_FW_IDEBUGSS_K3_WRAP_CV0_MAIN_0_VBUSP_CFG_FW_REGION_0_START_ADDRESS_L
0x5814 CBASS_FW_IPULSAR_SL_MAIN_0_CPU0_SLV_FW_REGION_0_START_ADDRESS_H — The FW Region 0 Start Address High Register defines the start address bits 47 to 32 for the target Ipulsar_sl_main_0.cpu0_slv region 0 firewall.
  fields as CBASS_FW_IDEBUGSS_K3_WRAP_CV0_MAIN_0_VBUSP_CFG_FW_REGION_0_START_ADDRESS_H
0x5818 CBASS_FW_IPULSAR_SL_MAIN_0_CPU0_SLV_FW_REGION_0_END_ADDRESS_L access per field reset 0x5C0FFFF — The FW Region 0 End Address Low Register defines the end address bits 31 to 0 to include for the target Ipulsar_sl_main_0.cpu0_slv region 0 firewall.
  fields as CBASS_FW_IDEBUGSS_K3_WRAP_CV0_MAIN_0_VBUSP_CFG_FW_REGION_0_END_ADDRESS_L
0x581C CBASS_FW_IPULSAR_SL_MAIN_0_CPU0_SLV_FW_REGION_0_END_ADDRESS_H — The FW Region 0 End Address High Register defines the end address bits 47 to 32 to include for the target Ipulsar_sl_main_0.cpu0_slv region 0 firewall.
  fields as CBASS_FW_IDEBUGSS_K3_WRAP_CV0_MAIN_0_VBUSP_CFG_FW_REGION_0_END_ADDRESS_H
0x5C00 CBASS_FW_IPULSAR_SL_MAIN_0_CPU1_SLV_FW_REGION_0_CONTROL access not given — The FW Region 0 Control Register defines the control fields for the target Ipulsar_sl_main_0.cpu1_slv region 0 firewall.
  fields as CBASS_FW_IDEBUGSS_K3_WRAP_CV0_MAIN_0_VBUSP_CFG_FW_REGION_0_CONTROL
{0x5C04+4i} CBASS_FW_IPULSAR_SL_MAIN_0_CPU1_SLV_FW_REGION_0_PERMISSION_{i} (i=0..2) — The FW Region 0 Permission {i} Register defines the permissions for the target Ipulsar_sl_main_0.cpu1_slv region 0 firewall.
  fields as CBASS_FW_IDEBUGSS_K3_WRAP_CV0_MAIN_0_VBUSP_CFG_FW_REGION_0_PERMISSION_0
0x5C10 CBASS_FW_IPULSAR_SL_MAIN_0_CPU1_SLV_FW_REGION_0_START_ADDRESS_L access per field reset 0x5D00000 — The FW Region 0 Start Address Low Register defines the start address bits 31 to 0 for the target Ipulsar_sl_main_0.cpu1_slv region 0 firewall.
  fields as CBASS_FW_IDEBUGSS_K3_WRAP_CV0_MAIN_0_VBUSP_CFG_FW_REGION_0_START_ADDRESS_L
0x5C14 CBASS_FW_IPULSAR_SL_MAIN_0_CPU1_SLV_FW_REGION_0_START_ADDRESS_H — The FW Region 0 Start Address High Register defines the start address bits 47 to 32 for the target Ipulsar_sl_main_0.cpu1_slv region 0 firewall.
  fields as CBASS_FW_IDEBUGSS_K3_WRAP_CV0_MAIN_0_VBUSP_CFG_FW_REGION_0_START_ADDRESS_H
0x5C18 CBASS_FW_IPULSAR_SL_MAIN_0_CPU1_SLV_FW_REGION_0_END_ADDRESS_L access per field reset 0x5D07FFF — The FW Region 0 End Address Low Register defines the end address bits 31 to 0 to include for the target Ipulsar_sl_main_0.cpu1_slv region 0 firewall.
  fields as CBASS_FW_IDEBUGSS_K3_WRAP_CV0_MAIN_0_VBUSP_CFG_FW_REGION_0_END_ADDRESS_L
0x5C1C CBASS_FW_IPULSAR_SL_MAIN_0_CPU1_SLV_FW_REGION_0_END_ADDRESS_H — The FW Region 0 End Address High Register defines the end address bits 47 to 32 to include for the target Ipulsar_sl_main_0.cpu1_slv region 0 firewall.
  fields as CBASS_FW_IDEBUGSS_K3_WRAP_CV0_MAIN_0_VBUSP_CFG_FW_REGION_0_END_ADDRESS_H
0x6000 CBASS_FW_IPULSAR_SL_MAIN_1_CPU0_SLV_FW_REGION_0_CONTROL access not given — The FW Region 0 Control Register defines the control fields for the target Ipulsar_sl_main_1.cpu0_slv region 0 firewall.
  fields as CBASS_FW_IDEBUGSS_K3_WRAP_CV0_MAIN_0_VBUSP_CFG_FW_REGION_0_CONTROL
{0x6004+4i} CBASS_FW_IPULSAR_SL_MAIN_1_CPU0_SLV_FW_REGION_0_PERMISSION_{i} (i=0..2) — The FW Region 0 Permission {i} Register defines the permissions for the target Ipulsar_sl_main_1.cpu0_slv region 0 firewall.
  fields as CBASS_FW_IDEBUGSS_K3_WRAP_CV0_MAIN_0_VBUSP_CFG_FW_REGION_0_PERMISSION_0
0x6010 CBASS_FW_IPULSAR_SL_MAIN_1_CPU0_SLV_FW_REGION_0_START_ADDRESS_L access per field reset 0x5E00000 — The FW Region 0 Start Address Low Register defines the start address bits 31 to 0 for the target Ipulsar_sl_main_1.cpu0_slv region 0 firewall.
  fields as CBASS_FW_IDEBUGSS_K3_WRAP_CV0_MAIN_0_VBUSP_CFG_FW_REGION_0_START_ADDRESS_L
0x6014 CBASS_FW_IPULSAR_SL_MAIN_1_CPU0_SLV_FW_REGION_0_START_ADDRESS_H — The FW Region 0 Start Address High Register defines the start address bits 47 to 32 for the target Ipulsar_sl_main_1.cpu0_slv region 0 firewall.
  fields as CBASS_FW_IDEBUGSS_K3_WRAP_CV0_MAIN_0_VBUSP_CFG_FW_REGION_0_START_ADDRESS_H
0x6018 CBASS_FW_IPULSAR_SL_MAIN_1_CPU0_SLV_FW_REGION_0_END_ADDRESS_L access per field reset 0x5E0FFFF — The FW Region 0 End Address Low Register defines the end address bits 31 to 0 to include for the target Ipulsar_sl_main_1.cpu0_slv region 0 firewall.
  fields as CBASS_FW_IDEBUGSS_K3_WRAP_CV0_MAIN_0_VBUSP_CFG_FW_REGION_0_END_ADDRESS_L
0x601C CBASS_FW_IPULSAR_SL_MAIN_1_CPU0_SLV_FW_REGION_0_END_ADDRESS_H — The FW Region 0 End Address High Register defines the end address bits 47 to 32 to include for the target Ipulsar_sl_main_1.cpu0_slv region 0 firewall.
  fields as CBASS_FW_IDEBUGSS_K3_WRAP_CV0_MAIN_0_VBUSP_CFG_FW_REGION_0_END_ADDRESS_H
0x6400 CBASS_FW_IPULSAR_SL_MAIN_1_CPU1_SLV_FW_REGION_0_CONTROL access not given — The FW Region 0 Control Register defines the control fields for the target Ipulsar_sl_main_1.cpu1_slv region 0 firewall.
  fields as CBASS_FW_IDEBUGSS_K3_WRAP_CV0_MAIN_0_VBUSP_CFG_FW_REGION_0_CONTROL
{0x6404+4i} CBASS_FW_IPULSAR_SL_MAIN_1_CPU1_SLV_FW_REGION_0_PERMISSION_{i} (i=0..2) — The FW Region 0 Permission {i} Register defines the permissions for the target Ipulsar_sl_main_1.cpu1_slv region 0 firewall.
  fields as CBASS_FW_IDEBUGSS_K3_WRAP_CV0_MAIN_0_VBUSP_CFG_FW_REGION_0_PERMISSION_0
0x6410 CBASS_FW_IPULSAR_SL_MAIN_1_CPU1_SLV_FW_REGION_0_START_ADDRESS_L access per field reset 0x5F00000 — The FW Region 0 Start Address Low Register defines the start address bits 31 to 0 for the target Ipulsar_sl_main_1.cpu1_slv region 0 firewall.
  fields as CBASS_FW_IDEBUGSS_K3_WRAP_CV0_MAIN_0_VBUSP_CFG_FW_REGION_0_START_ADDRESS_L
0x6414 CBASS_FW_IPULSAR_SL_MAIN_1_CPU1_SLV_FW_REGION_0_START_ADDRESS_H — The FW Region 0 Start Address High Register defines the start address bits 47 to 32 for the target Ipulsar_sl_main_1.cpu1_slv region 0 firewall.
  fields as CBASS_FW_IDEBUGSS_K3_WRAP_CV0_MAIN_0_VBUSP_CFG_FW_REGION_0_START_ADDRESS_H
0x6418 CBASS_FW_IPULSAR_SL_MAIN_1_CPU1_SLV_FW_REGION_0_END_ADDRESS_L access per field reset 0x5F07FFF — The FW Region 0 End Address Low Register defines the end address bits 31 to 0 to include for the target Ipulsar_sl_main_1.cpu1_slv region 0 firewall.
  fields as CBASS_FW_IDEBUGSS_K3_WRAP_CV0_MAIN_0_VBUSP_CFG_FW_REGION_0_END_ADDRESS_L
0x641C CBASS_FW_IPULSAR_SL_MAIN_1_CPU1_SLV_FW_REGION_0_END_ADDRESS_H — The FW Region 0 End Address High Register defines the end address bits 47 to 32 to include for the target Ipulsar_sl_main_1.cpu1_slv region 0 firewall.
  fields as CBASS_FW_IDEBUGSS_K3_WRAP_CV0_MAIN_0_VBUSP_CFG_FW_REGION_0_END_ADDRESS_H
